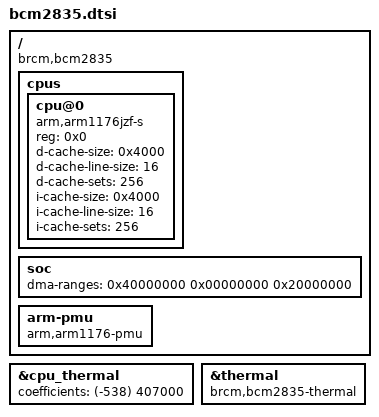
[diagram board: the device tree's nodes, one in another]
#include "bcm283x.dtsi"
#include "bcm2835-common.dtsi"
/ {
	compatible = "brcm,bcm2835";
	cpus {
		#address-cells = <1>;
		#size-cells = <0>;
		cpu@0 {
			device_type = "cpu";
			compatible = "arm,arm1176jzf-s";
			reg = <0x0>;
			d-cache-size = <0x4000>;
			d-cache-line-size = <16>;
			d-cache-sets = <256>;  
			i-cache-size = <0x4000>;
			i-cache-line-size = <16>;
			i-cache-sets = <256>;  
		};
	};
	soc {
		ranges = <0x7e000000 0x20000000 0x02000000>;
		dma-ranges = <0x40000000 0x00000000 0x20000000>;
	};
	arm-pmu {
		compatible = "arm,arm1176-pmu";
	};
};
&cpu_thermal {
	coefficients = <(-538)	407000>;
};
&thermal {
	compatible = "brcm,bcm2835-thermal";
	status = "okay";
};
